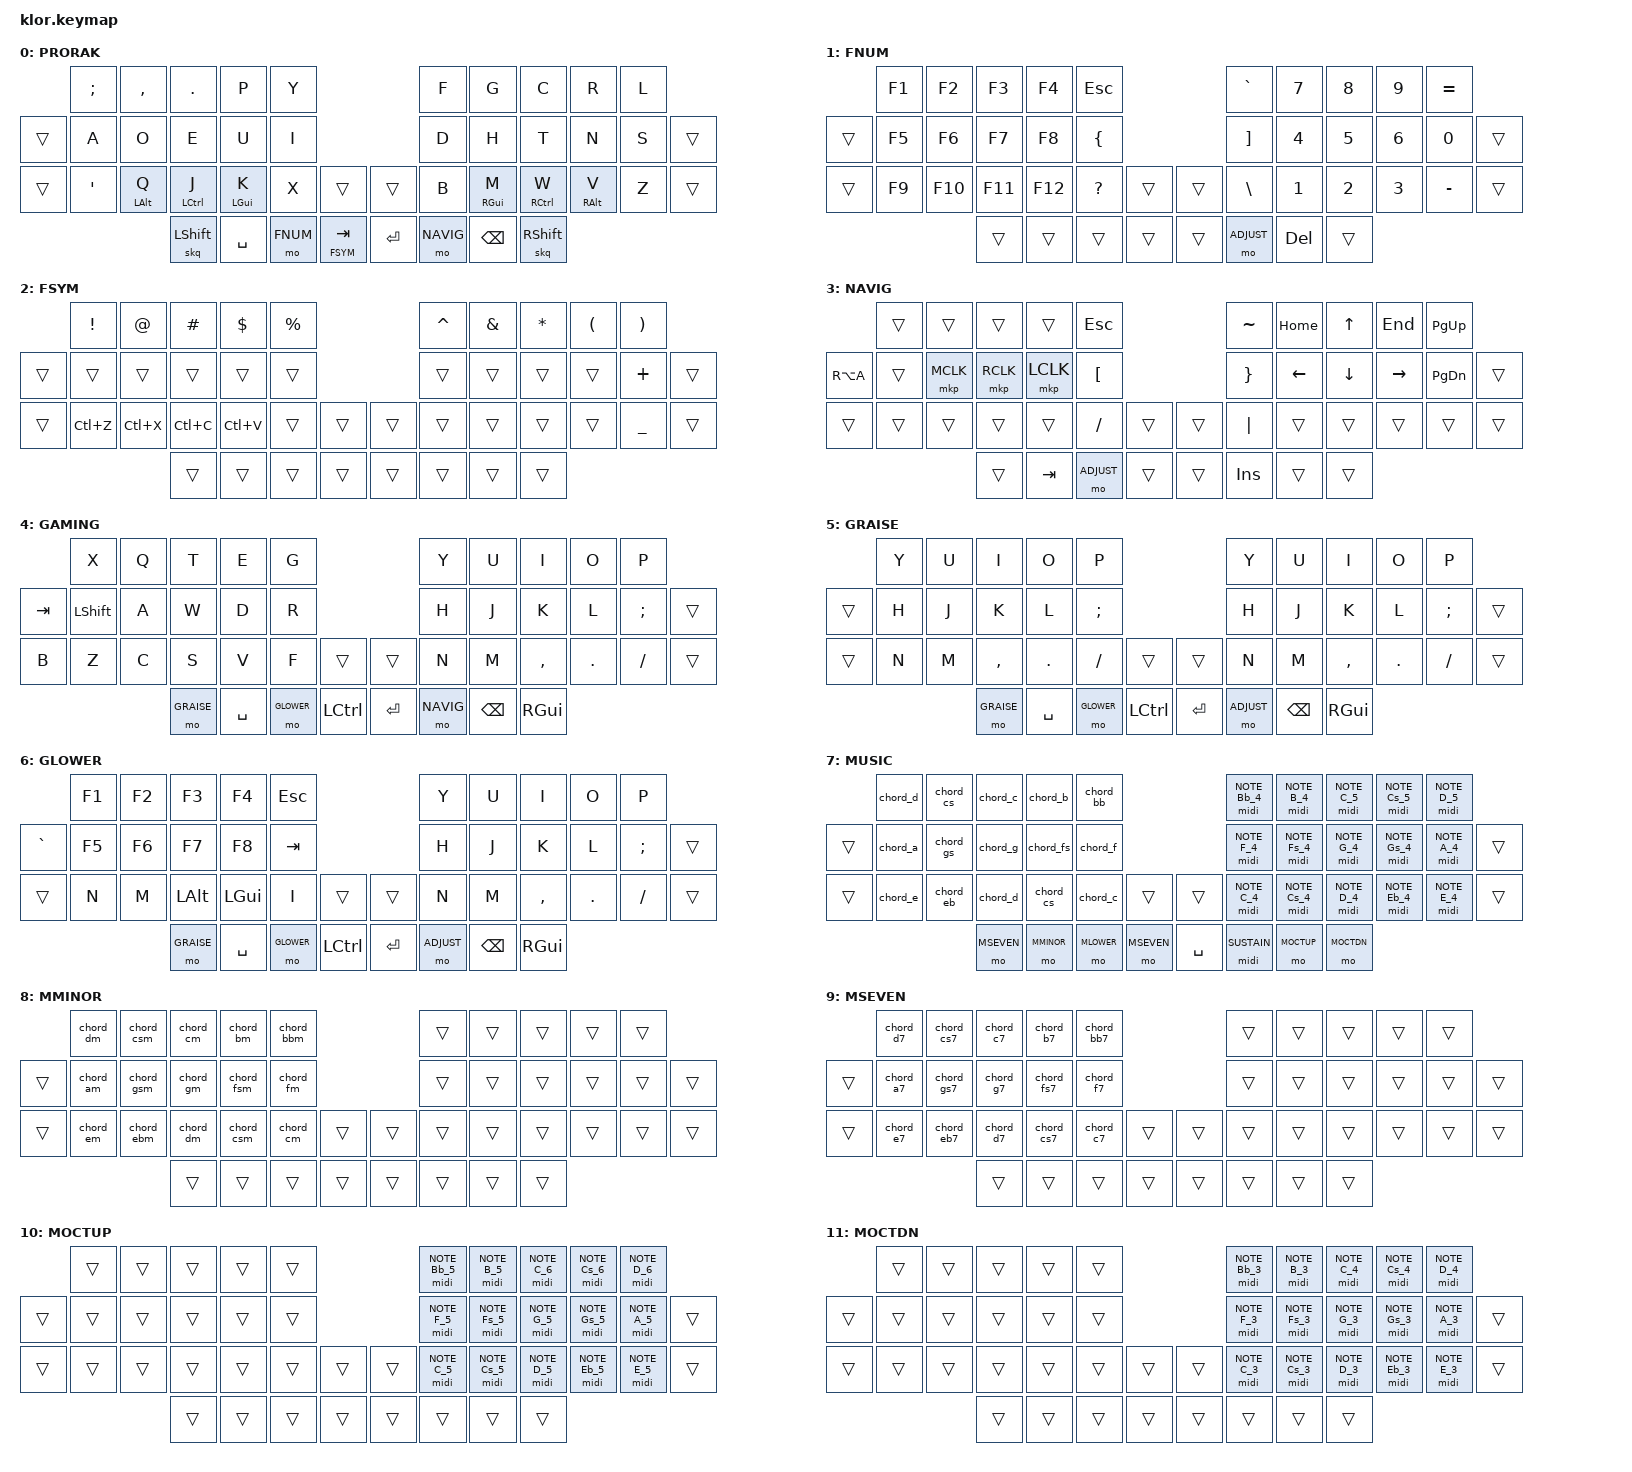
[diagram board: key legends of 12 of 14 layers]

//                               █         █    █            ▄▄▄▀▀▀▀▀▀▄▄▄        █▀▀▀▀▀▀▀▀▀▀█
//                               █        █     █          ▄▀            ▀▄      █          █
//                               █       █      █        ▄▀                ▀▄    █          █
//                               █      █       █        █                  █    █          █
//                               █     █        █       █                    █   █          █
//                               █    █         █       █                    █   █▄▄▄▄▄▄▄▄▄▄█
//                               █   █ █        █       █                    █   █      █
//                               █  █   █       █        █                  █    █       █
//                               █ █     █      █        ▀▄                ▄▀    █        █
//                               ██       █     █          ▀▄            ▄▀      █         █
//                               █         █    █▄▄▄▄▄▄▄▄    ▀▀▀▄▄▄▄▄▄▀▀▀        █          █
//
// ▄▄▄▄▄▄▄▄▄▄▄▄▄▄▄▄▄▄▄▄▄▄▄▄▄▄▄▄▄▄▄▄▄▄▄▄▄▄▄▄▄▄▄▄▄▄▄▄▄▄▄▄▄▄▄▄▄▄▄▄▄▄▄▄▄▄▄▄▄▄▄▄▄▄▄▄▄▄▄▄▄▄▄▄▄▄▄▄▄▄▄▄▄▄▄▄▄▄▄▄▄▄▄▄▄▄▄▄▄▄▄▄▄▄▄▄▄▄▄▄▄▄▄▄▄
       
#include <behaviors.dtsi>
#include <dt-bindings/zmk/keys.h>
#include <dt-bindings/zmk/bt.h>
#include <dt-bindings/zmk/outputs.h>
#include <dt-bindings/zmk/ext_power.h>
#include <dt-bindings/zmk/pointing.h>
#include <dt-bindings/zmk/midi.h>
#include <behaviors/midi_key_press.dtsi>
/* #include <dt-bindings/zmk/rgb.h> */


#define PRORAK 0
#define FNUM   1
#define FSYM   2
#define NAVIG  3
#define GAMING 4
#define GRAISE 5
#define GLOWER 6
#define MUSIC  7
#define MMINOR 8
#define MSEVEN 9
#define MOCTUP 10
#define MOCTDN 11
#define MLOWER 12
#define ADJUST 13


/* key positions
              ┌─────────┬─────────┬─────────┬─────────┬─────────┐                    ┌─────────┬─────────┬─────────┬─────────┬─────────┐
              │    0    │    1    │    2    │    3    │    4    │                    │    5    │    6    │    7    │    8    │    9    │   
    ┌─────────┼─────────┼─────────┼─────────┼─────────┼─────────┤                    ├─────────┼─────────┼─────────┼─────────┼─────────┼─────────┐
    │   10    │    11   │    12   │    13   │    14   │    15   │                    │    16   │    17   │    18   │    19   │    20   │    21   │
    ├─────────┼─────────┼─────────┼─────────┼─────────┼─────────┤╭────────╮╭────────╮├─────────┼─────────┼─────────┼─────────┼─────────┼─────────┤
    │   22    │    23   │    24   │    25   │    26   │    27   ││   28   ││   29   ││    30   │    31   │    32   │    33   │    34   │    35   │
    └─────────┴─────────┴─────────┼─────────┼─────────┼─────────┼╰────────╯╰────────╯┼─────────┼─────────┼─────────┼─────────┴─────────┴─────────┘
                                  │    36   │    37   │    38   │    39   ││   40    │    41   │    42   │    43   │
                                  └─────────┴─────────┴─────────┴─────────┘└─────────┴─────────┴─────────┴─────────┘ */ 

/ {
    behaviors {
        hml: left_hand_mods {
            compatible = "zmk,behavior-hold-tap";
            label = "BOTTOMROW_MODS_LEFT";
            #binding-cells = <2>;
            tapping-term-ms = <170>;
            require-prior-idle-ms = <110>; // prevents firing during fast typing rolls
            quick-tap-ms = <100>; // tap-hold to spam keys, default 0
            //  the whitelisted key will trigger the mod key immediately
            hold-trigger-key-positions = <
                                          5  6  7  8  9
                                         16 17 18 19 20 21
                                         30 31 32 33 34 35
                                      40 41    43

                    24 25 26
                       36    38 39
            >;
            // flavor = "tap-preferred";
            flavor = "balanced"; // apply modifiers immediately when a key on the other half is pressed
            bindings = <&kp>, <&kp>;

        };
        hmr: right_hand_mods {
            compatible = "zmk,behavior-hold-tap";
            label = "BOTTOMROW_MODS_RIGHT";
            #binding-cells = <2>;
            tapping-term-ms = <170>;
            require-prior-idle-ms = <110>; // prevents firing during fast typing rolls
            quick-tap-ms = <100>; // tap-hold to spam keys, default 0
            //  the whitelisted key will trigger the mod key immediately
            hold-trigger-key-positions = <
                                            31 32 33
                                      40 41    43

                  0  1  2  3  4
              10 11 12 13 14 15
              22 23 24 25 26 27
                       36    38 39
            >;
            // flavor = "tap-preferred";
            flavor = "balanced"; // apply modifiers immediately when a key the other half is pressed
            bindings = <&kp>, <&kp>;

        };
        skq: sticky_key_quick_release {
            compatible = "zmk,behavior-sticky-key";
            #binding-cells = <1>;
            bindings = <&kp>;
            release-after-ms = <500>;
            quick-release; // Release after a button is pressed (to avoid rolling CAPS)
            ignore-modifiers;  // Recommended for shift
        };

        lt_tmb: layer_tap_thumb {
            compatible = "zmk,behavior-hold-tap";
            label = "LAYER_TAP_THUMB";
            #binding-cells = <2>;
            tapping-term-ms = <200>;
            quick-tap-ms = <100>;
            flavor = "hold-preferred"; // allows fast rolls
            bindings = <&mo>, <&kp>;
        };

    };

     combos {
            compatible = "zmk,combos";
            combo_adjust {
              timeout-ms = <50>;
              key-positions = <40 42>; // ENTER + BSPC
              bindings = <&mo ADJUST>;
            };
            combo_caps_word {
              timeout-ms = <50>;
              key-positions = <36 43>; // LSHFT (Left most Thumb) + RSHFT (Right most Thumb)
              bindings = <&caps_word>;
            };
    };

    macros {
        // --- 12 Major Chords ---
        chord_c: chord_c {
            compatible = "zmk,behavior-macro";
            #binding-cells = <0>;
            bindings = <&macro_press &midi NOTE_C_4 &midi NOTE_E_4 &midi NOTE_G_4>
                     , <&macro_pause_for_release>
                     , <&macro_release &midi NOTE_C_4 &midi NOTE_E_4 &midi NOTE_G_4>;
        };

        chord_cs: chord_cs {
            compatible = "zmk,behavior-macro";
            #binding-cells = <0>;
            bindings = <&macro_press &midi NOTE_Cs_4 &midi NOTE_F_4 &midi NOTE_Gs_4>
                     , <&macro_pause_for_release>
                     , <&macro_release &midi NOTE_Cs_4 &midi NOTE_F_4 &midi NOTE_Gs_4>;
        };

        chord_d: chord_d {
            compatible = "zmk,behavior-macro";
            #binding-cells = <0>;
            bindings = <&macro_press &midi NOTE_D_4 &midi NOTE_Fs_4 &midi NOTE_A_4>
                     , <&macro_pause_for_release>
                     , <&macro_release &midi NOTE_D_4 &midi NOTE_Fs_4 &midi NOTE_A_4>;
        };

        chord_eb: chord_eb {
            compatible = "zmk,behavior-macro";
            #binding-cells = <0>;
            bindings = <&macro_press &midi NOTE_Eb_4 &midi NOTE_G_4 &midi NOTE_Bb_4>
                     , <&macro_pause_for_release>
                     , <&macro_release &midi NOTE_Eb_4 &midi NOTE_G_4 &midi NOTE_Bb_4>;
        };

        chord_e: chord_e {
            compatible = "zmk,behavior-macro";
            #binding-cells = <0>;
            bindings = <&macro_press &midi NOTE_E_4 &midi NOTE_Gs_4 &midi NOTE_B_4>
                     , <&macro_pause_for_release>
                     , <&macro_release &midi NOTE_E_4 &midi NOTE_Gs_4 &midi NOTE_B_4>;
        };

        chord_f: chord_f {
            compatible = "zmk,behavior-macro";
            #binding-cells = <0>;
            bindings = <&macro_press &midi NOTE_F_4 &midi NOTE_A_4 &midi NOTE_C_5>
                     , <&macro_pause_for_release>
                     , <&macro_release &midi NOTE_F_4 &midi NOTE_A_4 &midi NOTE_C_5>;
        };

        chord_fs: chord_fs {
            compatible = "zmk,behavior-macro";
            #binding-cells = <0>;
            bindings = <&macro_press &midi NOTE_Fs_4 &midi NOTE_Bb_4 &midi NOTE_Cs_5>
                     , <&macro_pause_for_release>
                     , <&macro_release &midi NOTE_Fs_4 &midi NOTE_Bb_4 &midi NOTE_Cs_5>;
        };

        chord_g: chord_g {
            compatible = "zmk,behavior-macro";
            #binding-cells = <0>;
            bindings = <&macro_press &midi NOTE_G_4 &midi NOTE_B_4 &midi NOTE_D_5>
                     , <&macro_pause_for_release>
                     , <&macro_release &midi NOTE_G_4 &midi NOTE_B_4 &midi NOTE_D_5>;
        };

        chord_gs: chord_gs {
            compatible = "zmk,behavior-macro";
            #binding-cells = <0>;
            bindings = <&macro_press &midi NOTE_Gs_4 &midi NOTE_C_5 &midi NOTE_Eb_5>
                     , <&macro_pause_for_release>
                     , <&macro_release &midi NOTE_Gs_4 &midi NOTE_C_5 &midi NOTE_Eb_5>;
        };

        chord_a: chord_a {
            compatible = "zmk,behavior-macro";
            #binding-cells = <0>;
            bindings = <&macro_press &midi NOTE_A_4 &midi NOTE_Cs_5 &midi NOTE_E_5>
                     , <&macro_pause_for_release>
                     , <&macro_release &midi NOTE_A_4 &midi NOTE_Cs_5 &midi NOTE_E_5>;
        };

        chord_bb: chord_bb {
            compatible = "zmk,behavior-macro";
            #binding-cells = <0>;
            bindings = <&macro_press &midi NOTE_Bb_4 &midi NOTE_D_5 &midi NOTE_F_5>
                     , <&macro_pause_for_release>
                     , <&macro_release &midi NOTE_Bb_4 &midi NOTE_D_5 &midi NOTE_F_5>;
        };

        chord_b: chord_b {
            compatible = "zmk,behavior-macro";
            #binding-cells = <0>;
            bindings = <&macro_press &midi NOTE_B_4 &midi NOTE_Ds_5 &midi NOTE_Fs_5>
                     , <&macro_pause_for_release>
                     , <&macro_release &midi NOTE_B_4 &midi NOTE_Ds_5 &midi NOTE_Fs_5>;
        };

        // --- 12 Minor Chords ---
        chord_cm: chord_cm {
            compatible = "zmk,behavior-macro";
            #binding-cells = <0>;
            bindings = <&macro_press &midi NOTE_C_4 &midi NOTE_Eb_4 &midi NOTE_G_4>
                     , <&macro_pause_for_release>
                     , <&macro_release &midi NOTE_C_4 &midi NOTE_Eb_4 &midi NOTE_G_4>;
        };

        chord_csm: chord_csm {
            compatible = "zmk,behavior-macro";
            #binding-cells = <0>;
            bindings = <&macro_press &midi NOTE_Cs_4 &midi NOTE_E_4 &midi NOTE_Gs_4>
                     , <&macro_pause_for_release>
                     , <&macro_release &midi NOTE_Cs_4 &midi NOTE_E_4 &midi NOTE_Gs_4>;
        };

        chord_dm: chord_dm {
            compatible = "zmk,behavior-macro";
            #binding-cells = <0>;
            bindings = <&macro_press &midi NOTE_D_4 &midi NOTE_F_4 &midi NOTE_A_4>
                     , <&macro_pause_for_release>
                     , <&macro_release &midi NOTE_D_4 &midi NOTE_F_4 &midi NOTE_A_4>;
        };

        chord_ebm: chord_ebm {
            compatible = "zmk,behavior-macro";
            #binding-cells = <0>;
            bindings = <&macro_press &midi NOTE_Eb_4 &midi NOTE_Fs_4 &midi NOTE_Bb_4>
                     , <&macro_pause_for_release>
                     , <&macro_release &midi NOTE_Eb_4 &midi NOTE_Fs_4 &midi NOTE_Bb_4>;
        };

        chord_em: chord_em {
            compatible = "zmk,behavior-macro";
            #binding-cells = <0>;
            bindings = <&macro_press &midi NOTE_E_4 &midi NOTE_G_4 &midi NOTE_B_4>
                     , <&macro_pause_for_release>
                     , <&macro_release &midi NOTE_E_4 &midi NOTE_G_4 &midi NOTE_B_4>;
        };

        chord_fm: chord_fm {
            compatible = "zmk,behavior-macro";
            #binding-cells = <0>;
            bindings = <&macro_press &midi NOTE_F_4 &midi NOTE_Gs_4 &midi NOTE_C_5>
                     , <&macro_pause_for_release>
                     , <&macro_release &midi NOTE_F_4 &midi NOTE_Gs_4 &midi NOTE_C_5>;
        };

        chord_fsm: chord_fsm {
            compatible = "zmk,behavior-macro";
            #binding-cells = <0>;
            bindings = <&macro_press &midi NOTE_Fs_4 &midi NOTE_A_4 &midi NOTE_Cs_5>
                     , <&macro_pause_for_release>
                     , <&macro_release &midi NOTE_Fs_4 &midi NOTE_A_4 &midi NOTE_Cs_5>;
        };

        chord_gm: chord_gm {
            compatible = "zmk,behavior-macro";
            #binding-cells = <0>;
            bindings = <&macro_press &midi NOTE_G_4 &midi NOTE_Bb_4 &midi NOTE_D_5>
                     , <&macro_pause_for_release>
                     , <&macro_release &midi NOTE_G_4 &midi NOTE_Bb_4 &midi NOTE_D_5>;
        };

        chord_gsm: chord_gsm {
            compatible = "zmk,behavior-macro";
            #binding-cells = <0>;
            bindings = <&macro_press &midi NOTE_Gs_4 &midi NOTE_B_4 &midi NOTE_Eb_5>
                     , <&macro_pause_for_release>
                     , <&macro_release &midi NOTE_Gs_4 &midi NOTE_B_4 &midi NOTE_Eb_5>;
        };

        chord_am: chord_am {
            compatible = "zmk,behavior-macro";
            #binding-cells = <0>;
            bindings = <&macro_press &midi NOTE_A_4 &midi NOTE_C_5 &midi NOTE_E_5>
                     , <&macro_pause_for_release>
                     , <&macro_release &midi NOTE_A_4 &midi NOTE_C_5 &midi NOTE_E_5>;
        };

        chord_bbm: chord_bbm {
            compatible = "zmk,behavior-macro";
            #binding-cells = <0>;
            bindings = <&macro_press &midi NOTE_Bb_4 &midi NOTE_Cs_5 &midi NOTE_F_5>
                     , <&macro_pause_for_release>
                     , <&macro_release &midi NOTE_Bb_4 &midi NOTE_Cs_5 &midi NOTE_F_5>;
        };

        chord_bm: chord_bm {
            compatible = "zmk,behavior-macro";
            #binding-cells = <0>;
            bindings = <&macro_press &midi NOTE_B_4 &midi NOTE_D_5 &midi NOTE_Fs_5>
                     , <&macro_pause_for_release>
                     , <&macro_release &midi NOTE_B_4 &midi NOTE_D_5 &midi NOTE_Fs_5>;
        };

        // --- 12 Dominant 7th Chords ---
        chord_c7: chord_c7 {
            compatible = "zmk,behavior-macro";
            #binding-cells = <0>;
            bindings = <&macro_press &midi NOTE_C_4 &midi NOTE_E_4 &midi NOTE_G_4 &midi NOTE_Bb_4>
                     , <&macro_pause_for_release>
                     , <&macro_release &midi NOTE_C_4 &midi NOTE_E_4 &midi NOTE_G_4 &midi NOTE_Bb_4>;
        };

        chord_cs7: chord_cs7 {
            compatible = "zmk,behavior-macro";
            #binding-cells = <0>;
            bindings = <&macro_press &midi NOTE_Cs_4 &midi NOTE_F_4 &midi NOTE_Gs_4 &midi NOTE_B_4>
                     , <&macro_pause_for_release>
                     , <&macro_release &midi NOTE_Cs_4 &midi NOTE_F_4 &midi NOTE_Gs_4 &midi NOTE_B_4>;
        };

        chord_d7: chord_d7 {
            compatible = "zmk,behavior-macro";
            #binding-cells = <0>;
            bindings = <&macro_press &midi NOTE_D_4 &midi NOTE_Fs_4 &midi NOTE_A_4 &midi NOTE_C_5>
                     , <&macro_pause_for_release>
                     , <&macro_release &midi NOTE_D_4 &midi NOTE_Fs_4 &midi NOTE_A_4 &midi NOTE_C_5>;
        };

        chord_eb7: chord_eb7 {
            compatible = "zmk,behavior-macro";
            #binding-cells = <0>;
            bindings = <&macro_press &midi NOTE_Eb_4 &midi NOTE_G_4 &midi NOTE_Bb_4 &midi NOTE_Cs_5>
                     , <&macro_pause_for_release>
                     , <&macro_release &midi NOTE_Eb_4 &midi NOTE_G_4 &midi NOTE_Bb_4 &midi NOTE_Cs_5>;
        };

        chord_e7: chord_e7 {
            compatible = "zmk,behavior-macro";
            #binding-cells = <0>;
            bindings = <&macro_press &midi NOTE_E_4 &midi NOTE_Gs_4 &midi NOTE_B_4 &midi NOTE_D_5>
                     , <&macro_pause_for_release>
                     , <&macro_release &midi NOTE_E_4 &midi NOTE_Gs_4 &midi NOTE_B_4 &midi NOTE_D_5>;
        };

        chord_f7: chord_f7 {
            compatible = "zmk,behavior-macro";
            #binding-cells = <0>;
            bindings = <&macro_press &midi NOTE_F_4 &midi NOTE_A_4 &midi NOTE_C_5 &midi NOTE_Eb_5>
                     , <&macro_pause_for_release>
                     , <&macro_release &midi NOTE_F_4 &midi NOTE_A_4 &midi NOTE_C_5 &midi NOTE_Eb_5>;
        };

        chord_fs7: chord_fs7 {
            compatible = "zmk,behavior-macro";
            #binding-cells = <0>;
            bindings = <&macro_press &midi NOTE_Fs_4 &midi NOTE_Bb_4 &midi NOTE_Cs_5 &midi NOTE_E_5>
                     , <&macro_pause_for_release>
                     , <&macro_release &midi NOTE_Fs_4 &midi NOTE_Bb_4 &midi NOTE_Cs_5 &midi NOTE_E_5>;
        };

        chord_g7: chord_g7 {
            compatible = "zmk,behavior-macro";
            #binding-cells = <0>;
            bindings = <&macro_press &midi NOTE_G_4 &midi NOTE_B_4 &midi NOTE_D_5 &midi NOTE_F_5>
                     , <&macro_pause_for_release>
                     , <&macro_release &midi NOTE_G_4 &midi NOTE_B_4 &midi NOTE_D_5 &midi NOTE_F_5>;
        };

        chord_gs7: chord_gs7 {
            compatible = "zmk,behavior-macro";
            #binding-cells = <0>;
            bindings = <&macro_press &midi NOTE_Gs_4 &midi NOTE_C_5 &midi NOTE_Eb_5 &midi NOTE_Fs_5>
                     , <&macro_pause_for_release>
                     , <&macro_release &midi NOTE_Gs_4 &midi NOTE_C_5 &midi NOTE_Eb_5 &midi NOTE_Fs_5>;
        };

        chord_a7: chord_a7 {
            compatible = "zmk,behavior-macro";
            #binding-cells = <0>;
            bindings = <&macro_press &midi NOTE_A_4 &midi NOTE_Cs_5 &midi NOTE_E_5 &midi NOTE_G_5>
                     , <&macro_pause_for_release>
                     , <&macro_release &midi NOTE_A_4 &midi NOTE_Cs_5 &midi NOTE_E_5 &midi NOTE_G_5>;
        };

        chord_bb7: chord_bb7 {
            compatible = "zmk,behavior-macro";
            #binding-cells = <0>;
            bindings = <&macro_press &midi NOTE_Bb_4 &midi NOTE_D_5 &midi NOTE_F_5 &midi NOTE_Gs_5>
                     , <&macro_pause_for_release>
                     , <&macro_release &midi NOTE_Bb_4 &midi NOTE_D_5 &midi NOTE_F_5 &midi NOTE_Gs_5>;
        };

        chord_b7: chord_b7 {
            compatible = "zmk,behavior-macro";
            #binding-cells = <0>;
            bindings = <&macro_press &midi NOTE_B_4 &midi NOTE_Ds_5 &midi NOTE_Fs_5 &midi NOTE_A_5>
                     , <&macro_pause_for_release>
                     , <&macro_release &midi NOTE_B_4 &midi NOTE_Ds_5 &midi NOTE_Fs_5 &midi NOTE_A_5>;
        };
    };

    keymap {
        compatible = "zmk,keymap";
// ▄▄▄▄▄▄▄▄▄▄▄▄▄▄▄▄▄▄▄▄▄▄▄▄▄▄▄▄▄▄▄▄▄▄▄▄▄▄▄▄▄▄▄▄▄▄▄▄▄▄▄▄▄▄▄▄▄▄▄▄▄▄▄▄▄▄▄▄▄▄▄▄▄▄▄▄▄▄▄▄▄▄▄▄▄▄▄▄▄▄▄▄▄▄▄▄▄▄▄▄▄▄▄▄▄▄▄▄▄▄▄▄▄▄▄▄▄▄▄▄▄▄▄▄▄▄▄▄▄▄▄▄▄▄▄▄▄▄▄▄▄▄


                prorak_layer {
//  ┌───────────────────────────────────────────────────────────┐
label= "PRORAK"                                                 ;
//  └───────────────────────────────────────────────────────────┘
/*            ┌─────────┬─────────┬─────────┬─────────┬─────────┐                    ┌─────────┬─────────┬─────────┬─────────┬─────────┐
              │    ;    │    ,    │    .    │    P    │    Y    │                    │    F    │    G    │    C    │    R    │    L    │
    ┌─────────┼─────────┼─────────┼─────────┼─────────┼─────────┤                    ├─────────┼─────────┼─────────┼─────────┼─────────┼─────────┐
    │   XXX   │    A    │    O    │    E    │    U    │    I    │                    │    D    │    H    │    T    │    N    │    S    │   XXX   │
    ├─────────┼─────────┼─────────┼─────────┼─────────┼─────────┤╭────────╮╭────────╮├─────────┼─────────┼─────────┼─────────┼─────────┼─────────┤
    │   XXX   │    "    │ Q/LALT  │ J/LCTRL │ K/LGUI  │    X    ││  MUTE  ││PLY/PSE ││    B    │ M/RGUI  │ W/RCTRL │ V/RALT  │    Z    │   XXX   │
    └─────────┴─────────┴─────────┼─────────┼─────────┼─────────┼╰────────╯╰────────╯┼─────────┼─────────┼─────────┼─────────┴─────────┴─────────┘
                                  │  LSHFT  │  SPACE  │  FNUM   │ TAB/FSYM││  ENTER  │  NAVIG  │  BSPCE  │  RSHFT  │
                                  └─────────┴─────────┴─────────┴─────────┘└─────────┴─────────┴─────────┴─────────┘ */
 bindings = <
 //|          ╷         ╷           ╷            ╷           ╷         ╷               ╷╷         ╷         ╷           ╷            ╷           ╷         ╷
              &kp SEMI  &kp COMMA   &kp DOT      &kp P       &kp Y                                &kp F     &kp G       &kp C        &kp R       &kp L
    &trans    &kp A     &kp O       &kp E        &kp U       &kp I                                &kp D     &kp H       &kp T        &kp N       &kp S      &trans
    &trans    &kp SQT   &hml LALT Q &hml LCTRL J &hml LGUI K &kp X     &trans           &trans    &kp B     &hmr RGUI M &hmr RCTRL W &hmr RALT V &kp Z      &trans
                                    &skq LSHFT   &kp SPACE   &mo FNUM  &lt_tmb FSYM TAB &kp RET   &mo NAVIG &kp BSPC    &skq RSHFT
 //|          ╷         ╷           ╷            ╷           ╷         ╷               ╷╷         ╷         ╷           ╷            ╷           ╷         ╷
                        >;
            sensor-bindings = <&inc_dec_kp C_VOL_UP C_VOL_DN>;
                };

// ▄▄▄▄▄▄▄▄▄▄▄▄▄▄▄▄▄▄▄▄▄▄▄▄▄▄▄▄▄▄▄▄▄▄▄▄▄▄▄▄▄▄▄▄▄▄▄▄▄▄▄▄▄▄▄▄▄▄▄▄▄▄▄▄▄▄▄▄▄▄▄▄▄▄▄▄▄▄▄▄▄▄▄▄▄▄▄▄▄▄▄▄▄▄▄▄▄▄▄▄▄▄▄▄▄▄▄▄▄▄▄▄▄▄▄▄▄▄▄▄▄▄▄▄▄▄▄▄▄▄▄▄▄▄▄▄▄▄▄▄▄▄


                fnum_layer {
//  ┌───────────────────────────────────────────────────────────┐
label= "FNUM"                                                   ;
//  └───────────────────────────────────────────────────────────┘
/*            ┌─────────┬─────────┬─────────┬─────────┬─────────┐                    ┌─────────┬─────────┬─────────┬─────────┬─────────┐
              │   F1    │   F2    │   F3    │   F4    │   ESC   │                    │    `    │    7    │    8    │    9    │    0    │
    ┌─────────┼─────────┼─────────┼─────────┼─────────┼─────────┤                    ├─────────┼─────────┼─────────┼─────────┼─────────┼─────────┐
    │         │   F5    │   F6    │   F7    │   F8    │    {    │                    │    ]    │    4    │    5    │    6    │    =    │         │
    ├─────────┼─────────┼─────────┼─────────┼─────────┼─────────┤╭────────╮╭────────╮├─────────┼─────────┼─────────┼─────────┼─────────┼─────────┤
    │         │   F9    │   F10   │   F11   │   F12   │    ?    ││        ││        ││    \    │    1    │    2    │    3    │    -    │         │
    └─────────┴─────────┴─────────┼─────────┼─────────┼─────────┼╰────────╯╰────────╯┼─────────┼─────────┼─────────┼─────────┴─────────┴─────────┘
                                  │         │         │         │         ││         │  ADJUST │ DELETE  │         │  
                                  └─────────┴─────────┴─────────┴─────────┘└─────────┴─────────┴─────────┴─────────┘ */ 
 bindings = <
 //|          ╷         ╷         ╷         ╷         ╷         ╷         ╷╷         ╷         ╷         ╷         ╷         ╷         ╷
              &kp F1    &kp F2    &kp F3    &kp F4    &kp ESC                        &kp GRAVE &kp N7    &kp N8    &kp N9    &kp EQUAL
    &trans    &kp F5    &kp F6    &kp F7    &kp F8    &kp LBRC                       &kp RBKT  &kp N4    &kp N5    &kp N6    &kp N0    &trans
    &trans    &kp F9    &kp F10   &kp F11   &kp F12   &kp QMARK &trans     &trans    &kp BSLH  &kp N1    &kp N2    &kp N3    &kp MINUS &trans
                                  &trans    &trans    &trans    &trans     &trans    &mo ADJUST &kp DELETE &trans
                        >;
            sensor-bindings = <&inc_dec_kp C_VOL_UP C_VOL_DN>;
                };

// ▄▄▄▄▄▄▄▄▄▄▄▄▄▄▄▄▄▄▄▄▄▄▄▄▄▄▄▄▄▄▄▄▄▄▄▄▄▄▄▄▄▄▄▄▄▄▄▄▄▄▄▄▄▄▄▄▄▄▄▄▄▄▄▄▄▄▄▄▄▄▄▄▄▄▄▄▄▄▄▄▄▄▄▄▄▄▄▄▄▄▄▄▄▄▄▄▄▄▄▄▄▄▄▄▄▄▄▄▄▄▄▄▄▄▄▄▄▄▄▄▄▄▄▄▄

                fsym_layer {
//  ┌───────────────────────────────────────────────────────────┐
label= "FSYM"                                                   ;
//  └───────────────────────────────────────────────────────────┘
/*            ┌─────────┬─────────┬─────────┬─────────┬─────────┐                    ┌─────────┬─────────┬─────────┬─────────┬─────────┐
              │    !    │    @    │    #    │    $    │    %    │                    │    ^    │    &    │    *    │    (    │    )    │
    ┌─────────┼─────────┼─────────┼─────────┼─────────┼─────────┤                    ├─────────┼─────────┼─────────┼─────────┼─────────┼─────────┐
    │         │         │         │         │         │         │                    │         │         │         │         │    +    │         │
    ├─────────┼─────────┼─────────┼─────────┼─────────┼─────────┤╭────────╮╭────────╮├─────────┼─────────┼─────────┼─────────┼─────────┼─────────┤
    │         │   UNDO  │   CUT   │   COPY  │  PASTE  │         ││        ││        ││         │         │         │         │    _    │         │
    └─────────┴─────────┴─────────┼─────────┼─────────┼─────────┼╰────────╯╰────────╯┼─────────┼─────────┼─────────┼─────────┴─────────┴─────────┘
                                  │         │         │         │         ││         │         │         │         │
                                  └─────────┴─────────┴─────────┴─────────┘└─────────┴─────────┴─────────┴─────────┘ */
 bindings = <
 //|          ╷         ╷         ╷         ╷         ╷         ╷         ╷╷         ╷         ╷         ╷         ╷         ╷         ╷
              &kp EXCL  &kp AT    &kp HASH  &kp DLLR  &kp PRCNT                      &kp CARET &kp AMPS  &kp STAR  &kp LPAR  &kp RPAR
    &trans    &trans    &trans    &trans    &trans    &trans                         &trans    &trans    &trans    &trans    &kp PLUS  &trans
    &trans    &kp LC(Z) &kp LC(X) &kp LC(C) &kp LC(V) &trans    &trans     &trans    &trans    &trans    &trans    &trans    &kp UNDER &trans
                                  &trans    &trans    &trans    &trans     &trans    &trans    &trans    &trans
                        >;
                };

// ▄▄▄▄▄▄▄▄▄▄▄▄▄▄▄▄▄▄▄▄▄▄▄▄▄▄▄▄▄▄▄▄▄▄▄▄▄▄▄▄▄▄▄▄▄▄▄▄▄▄▄▄▄▄▄▄▄▄▄▄▄▄▄▄▄▄▄▄▄▄▄▄▄▄▄▄▄▄▄▄▄▄▄▄▄▄▄▄▄▄▄▄▄▄▄▄▄▄▄▄▄▄▄▄▄▄▄▄▄▄▄▄▄▄▄▄▄▄▄▄▄▄▄▄▄




                navig_layer {
//  ┌───────────────────────────────────────────────────────────┐
label= "NAVIG"                                                  ;
//  └───────────────────────────────────────────────────────────┘
/*           ┌─────────┬─────────┬─────────┬─────────┬─────────┐                    ┌─────────┬─────────┬─────────┬─────────┬─────────┐
             │         │         │         │         │   ESC   │                    │    ~    │   HOME  │   UP    │  END    │  PG UP  │
   ┌─────────┼─────────┼─────────┼─────────┼─────────┼─────────┤                    ├─────────┼─────────┼─────────┼─────────┼─────────┼─────────┐
   │         │         │ Mouse M │ Mouse R │ Mouse L │    [    │                    │    }    │   LEFT  │  DOWN   │  RIGHT  │ PG DOWN │         │
   ├─────────┼─────────┼─────────┼─────────┼─────────┼─────────┤╭────────╮╭────────╮├─────────┼─────────┼─────────┼─────────┼─────────┼─────────┤
   │         │         │         │         │         │    /    ││        ││        ││    |    │         │         │         │         │         │
   └─────────┴─────────┴─────────┼─────────┼─────────┼─────────┼╰────────╯╰────────╯┼─────────┼─────────┼─────────┼─────────┴─────────┴─────────┘
                                 │         │   TAB   │  ADJUST │         ││         │  INSERT │         │         │
                                 └─────────┴─────────┴─────────┴─────────┘└─────────┴─────────┴─────────┴─────────┘ */
 bindings = <
 //╷         ╷         ╷         ╷         ╷         ╷         ╷         ╷╷         ╷         ╷         ╷         ╷         ╷         ╷         ╷
              &trans    &trans    &trans    &trans    &kp ESC                        &kp TILDE  &kp HOME  &kp UP    &kp END   &kp PG_UP
    &kp RA(A) &trans    &mkp MCLK &mkp RCLK &mkp LCLK &kp LBKT                       &kp RBRC   &kp LEFT  &kp DOWN  &kp RIGHT &kp PG_DN &trans
    &trans    &trans    &trans    &trans    &trans    &kp FSLH  &trans     &trans    &kp PIPE   &trans    &trans    &trans    &trans    &trans
                                  &trans    &kp TAB   &mo ADJUST &trans    &trans    &kp INSERT &trans    &trans
                        >;
                sensor-bindings = <&inc_dec_kp C_VOL_UP C_VOL_DN>;
                };

// ▄▄▄▄▄▄▄▄▄▄▄▄▄▄▄▄▄▄▄▄▄▄▄▄▄▄▄▄▄▄▄▄▄▄▄▄▄▄▄▄▄▄▄▄▄▄▄▄▄▄▄▄▄▄▄▄▄▄▄▄▄▄▄▄▄▄▄▄▄▄▄▄▄▄▄▄▄▄▄▄▄▄▄▄▄▄▄▄▄▄▄▄▄▄▄▄▄▄▄▄▄▄▄▄▄▄▄▄▄▄▄▄▄▄▄▄▄▄▄▄▄▄▄▄▄▄▄▄▄▄▄▄▄▄▄▄▄▄▄▄▄▄


                gaming_layer {
//  ┌───────────────────────────────────────────────────────────┐
label= "GAMING"                                                 ;
//  └───────────────────────────────────────────────────────────┘
/*            ┌─────────┬─────────┬─────────┬─────────┬─────────┐                    ┌─────────┬─────────┬─────────┬─────────┬─────────┐
              │    V    │    Q    │    T    │    E    │    G    │                    │    Y    │    U    │    I    │    O    │    P    │
    ┌─────────┼─────────┼─────────┼─────────┼─────────┼─────────┤                    ├─────────┼─────────┼─────────┼─────────┼─────────┼─────────┐
    │   TAB   │  LSHFT  │    A    │    W    │    D    │    R    │                    │    H    │    J    │    K    │    L    │    ;    │   XXX   │
    ├─────────┼─────────┼─────────┼─────────┼─────────┼─────────┤╭────────╮╭────────╮├─────────┼─────────┼─────────┼─────────┼─────────┼─────────┤
    │    B    │    Z    │    C    │    S    │    X    │    F    ││  MUTE  ││PLY/PSE ││    N    │    M    │    ,    │    .    │    /    │   XXX   │
    └─────────┴─────────┴─────────┼─────────┼─────────┼─────────┼╰────────╯╰────────╯┼─────────┼─────────┼─────────┼─────────┴─────────┴─────────┘
                                  │  GRAISE │  SPACE  │  GLOWER │  LCTRL  ││  ENTER  │  NAVIG  │  BSPCE  │  RGUI   │
                                  └─────────┴─────────┴─────────┴─────────┘└─────────┴─────────┴─────────┴─────────┘ */
 bindings = <
 //|          ╷         ╷         ╷         ╷          ╷         ╷          ╷╷         ╷         ╷         ╷         ╷         ╷         ╷
              &kp X     &kp Q     &kp T     &kp E      &kp G                           &kp Y     &kp U     &kp I     &kp O     &kp P
    &kp TAB   &kp LSHFT &kp A     &kp W     &kp D      &kp R                           &kp H     &kp J     &kp K     &kp L     &kp SEMI  &trans
    &kp B     &kp Z     &kp C     &kp S     &kp V      &kp F     &trans     &trans     &kp N     &kp M     &kp COMMA &kp DOT   &kp FSLH  &trans
                                            &mo GRAISE &kp SPACE &mo GLOWER &kp LCTRL  &kp RET   &mo NAVIG &kp BSPC  &kp RGUI
                        >;
            sensor-bindings = <&inc_dec_kp C_VOL_UP C_VOL_DN>;
                };

// ▄▄▄▄▄▄▄▄▄▄▄▄▄▄▄▄▄▄▄▄▄▄▄▄▄▄▄▄▄▄▄▄▄▄▄▄▄▄▄▄▄▄▄▄▄▄▄▄▄▄▄▄▄▄▄▄▄▄▄▄▄▄▄▄▄▄▄▄▄▄▄▄▄▄▄▄▄▄▄▄▄▄▄▄▄▄▄▄▄▄▄▄▄▄▄▄▄▄▄▄▄▄▄▄▄▄▄▄▄▄▄▄▄▄▄▄▄▄▄▄▄▄▄▄▄▄▄▄▄▄▄▄▄▄▄▄▄▄▄▄▄▄


                gaming_raise_layer {
//  ┌───────────────────────────────────────────────────────────┐
label= "GRAISE"                                                 ;
//  └───────────────────────────────────────────────────────────┘
/*            ┌─────────┬─────────┬─────────┬─────────┬─────────┐                    ┌─────────┬─────────┬─────────┬─────────┬─────────┐
              │    Y    │    U    │    I    │    O    │    P    │                    │    Y    │    U    │    I    │    O    │    P    │
    ┌─────────┼─────────┼─────────┼─────────┼─────────┼─────────┤                    ├─────────┼─────────┼─────────┼─────────┼─────────┼─────────┐
    │   XXX   │    H    │    J    │    K    │    L    │    ;    │                    │    H    │    J    │    K    │    L    │    ;    │   XXX   │
    ├─────────┼─────────┼─────────┼─────────┼─────────┼─────────┤╭────────╮╭────────╮├─────────┼─────────┼─────────┼─────────┼─────────┼─────────┤
    │   XXX   │    N    │    M    │    ,    │    .    │    /    ││  MUTE  ││PLY/PSE ││    N    │    M    │    ,    │    .    │    /    │   XXX   │
    └─────────┴─────────┴─────────┼─────────┼─────────┼─────────┼╰────────╯╰────────╯┼─────────┼─────────┼─────────┼─────────┴─────────┴─────────┘
                                  │  GRAISE │  SPACE  │  GLOWER │  LCTRL  ││  ENTER  │  NAVIG  │  BSPCE  │  RGUI   │
                                  └─────────┴─────────┴─────────┴─────────┘└─────────┴─────────┴─────────┴─────────┘ */
 bindings = <
 //|          ╷         ╷         ╷         ╷          ╷         ╷          ╷╷         ╷         ╷          ╷         ╷         ╷         ╷
              &kp Y     &kp U     &kp I     &kp O      &kp P                           &kp Y     &kp U      &kp I     &kp O     &kp P
    &trans    &kp H     &kp J     &kp K     &kp L      &kp SEMI                        &kp H     &kp J      &kp K     &kp L     &kp SEMI  &trans
    &trans    &kp N     &kp M     &kp COMMA &kp DOT    &kp FSLH  &trans     &trans     &kp N     &kp M      &kp COMMA &kp DOT   &kp FSLH  &trans
                                            &mo GRAISE &kp SPACE &mo GLOWER &kp LCTRL  &kp RET   &mo ADJUST &kp BSPC &kp RGUI
                        >;
            sensor-bindings = <&inc_dec_kp C_VOL_UP C_VOL_DN>;
                };

// ▄▄▄▄▄▄▄▄▄▄▄▄▄▄▄▄▄▄▄▄▄▄▄▄▄▄▄▄▄▄▄▄▄▄▄▄▄▄▄▄▄▄▄▄▄▄▄▄▄▄▄▄▄▄▄▄▄▄▄▄▄▄▄▄▄▄▄▄▄▄▄▄▄▄▄▄▄▄▄▄▄▄▄▄▄▄▄▄▄▄▄▄▄▄▄▄▄▄▄▄▄▄▄▄▄▄▄▄▄▄▄▄▄▄▄▄▄▄▄▄▄▄▄▄▄▄▄▄▄▄▄▄▄▄▄▄▄▄▄▄▄▄


                gaming_lower_layer {
//  ┌───────────────────────────────────────────────────────────┐
label= "GLOWER"                                                 ;
//  └───────────────────────────────────────────────────────────┘
/*            ┌─────────┬─────────┬─────────┬─────────┬─────────┐                    ┌─────────┬─────────┬─────────┬─────────┬─────────┐
              │    F1   │    F2   │    F3   │    F4   │   ESC   │                    │    Y    │    U    │    I    │    O    │    P    │
    ┌─────────┼─────────┼─────────┼─────────┼─────────┼─────────┤                    ├─────────┼─────────┼─────────┼─────────┼─────────┼─────────┐
    │   GRV   │    F5   │    F6   │    F7   │    F8   │   TAB   │                    │    H    │    J    │    K    │    L    │    ;    │   XXX   │
    ├─────────┼─────────┼─────────┼─────────┼─────────┼─────────┤╭────────╮╭────────╮├─────────┼─────────┼─────────┼─────────┼─────────┼─────────┤
    │   XXX   │    N    │    M    │   LALT  │  LGUI   │    I    ││  MUTE  ││PLY/PSE ││    N    │    M    │    ,    │    .    │    /    │   XXX   │
    └─────────┴─────────┴─────────┼─────────┼─────────┼─────────┼╰────────╯╰────────╯┼─────────┼─────────┼─────────┼─────────┴─────────┴─────────┘
                                  │  GRAISE │  SPACE  │  GLOWER │  LCTRL  ││  ENTER  │  ADJUST │  BSPCE  │  RGUI   │
                                  └─────────┴─────────┴─────────┴─────────┘└─────────┴─────────┴─────────┴─────────┘ */
 bindings = <
 //|          ╷         ╷         ╷         ╷          ╷         ╷          ╷╷         ╷         ╷         ╷         ╷         ╷         ╷
              &kp F1    &kp F2    &kp F3    &kp F4     &kp ESC                         &kp Y     &kp U     &kp I     &kp O     &kp P
    &kp GRAVE &kp F5    &kp F6    &kp F7    &kp F8     &kp TAB                         &kp H     &kp J     &kp K     &kp L     &kp SEMI  &trans
    &trans    &kp N     &kp M     &kp LALT  &kp LGUI   &kp I     &trans     &trans     &kp N     &kp M     &kp COMMA &kp DOT   &kp FSLH  &trans
                                            &mo GRAISE &kp SPACE &mo GLOWER &kp LCTRL  &kp RET   &mo ADJUST &kp BSPC &kp RGUI
                        >;
            sensor-bindings = <&inc_dec_kp C_VOL_UP C_VOL_DN>;
                };

// ▄▄▄▄▄▄▄▄▄▄▄▄▄▄▄▄▄▄▄▄▄▄▄▄▄▄▄▄▄▄▄▄▄▄▄▄▄▄▄▄▄▄▄▄▄▄▄▄▄▄▄▄▄▄▄▄▄▄▄▄▄▄▄▄▄▄▄▄▄▄▄▄▄▄▄▄▄▄▄▄▄▄▄▄▄▄▄▄▄▄▄▄▄▄▄▄▄▄▄▄▄▄▄▄▄▄▄▄▄▄▄▄▄▄▄▄▄▄▄▄▄▄▄▄▄


                music_layer {
//  ┌───────────────────────────────────────────────────────────┐
label= "MUSIC"                                                  ;
//  └───────────────────────────────────────────────────────────┘
/*            ┌─────────┬─────────┬─────────┬─────────┬─────────┐                    ┌─────────┬─────────┬─────────┬─────────┬─────────┐
              │    D    │   C#    │    C    │    B    │   Bb    │                    │   Bb4   │   B4    │   C5    │   C#5   │   D5    │
    ┌─────────┼─────────┼─────────┼─────────┼─────────┼─────────┤                    ├─────────┼─────────┼─────────┼─────────┼─────────┼─────────┐
    │   XXX   │    A    │   G#    │    G    │   F#    │    F    │                    │   F4    │   F#4   │   G4    │   G#4   │   A4    │   XXX   │
    ├─────────┼─────────┼─────────┼─────────┼─────────┼─────────┤╭────────╮╭────────╮├─────────┼─────────┼─────────┼─────────┼─────────┼─────────┤
    │   XXX   │    E    │   Eb    │    D    │   C#    │    C    ││  MUTE  ││PLY/PSE ││   C4    │   C#4   │   D4    │   Eb4   │   E4    │   XXX   │
    └─────────┴─────────┴─────────┼─────────┼─────────┼─────────┼╰────────╯╰────────╯┼─────────┼─────────┼─────────┼─────────┴─────────┴─────────┘
                                  │  MSEVEN │  MMINOR │  MLOWER │  MSEVEN ││  SPACE  │ SUSTAIN │ MOCTUP  │ MOCTDN  │
                                  └─────────┴─────────┴─────────┴─────────┘└─────────┴─────────┴─────────┴─────────┘ */
 bindings = <
 //|          ╷          ╷          ╷          ╷          ╷          ╷          ╷╷         ╷               ╷               ╷               ╷               ╷               ╷
              &chord_d   &chord_cs  &chord_c   &chord_b   &chord_bb                        &midi NOTE_Bb_4 &midi NOTE_B_4  &midi NOTE_C_5  &midi NOTE_Cs_5 &midi NOTE_D_5
    &trans    &chord_a   &chord_gs  &chord_g   &chord_fs  &chord_f                         &midi NOTE_F_4  &midi NOTE_Fs_4 &midi NOTE_G_4  &midi NOTE_Gs_4 &midi NOTE_A_4  &trans
    &trans    &chord_e   &chord_eb  &chord_d   &chord_cs  &chord_c   &trans     &trans     &midi NOTE_C_4  &midi NOTE_Cs_4 &midi NOTE_D_4  &midi NOTE_Eb_4 &midi NOTE_E_4  &trans
                                    &mo MSEVEN &mo MMINOR &mo MLOWER &mo MSEVEN &kp SPACE  &midi SUSTAIN   &mo MOCTUP      &mo MOCTDN
            >;
    sensor-bindings = <&inc_dec_kp C_VOL_UP C_VOL_DN>;
                };

// ▄▄▄▄▄▄▄▄▄▄▄▄▄▄▄▄▄▄▄▄▄▄▄▄▄▄▄▄▄▄▄▄▄▄▄▄▄▄▄▄▄▄▄▄▄▄▄▄▄▄▄▄▄▄▄▄▄▄▄▄▄▄▄▄▄▄▄▄▄▄▄▄▄▄▄▄▄▄▄▄▄▄▄▄▄▄▄▄▄▄▄▄▄▄▄▄▄▄▄▄▄▄▄▄▄▄▄▄▄▄▄▄▄▄▄▄▄▄▄▄▄▄▄▄▄


                mminor_layer {
//  ┌───────────────────────────────────────────────────────────┐
label= "MMINOR"                                                 ;
//  └───────────────────────────────────────────────────────────┘
 bindings = <
 //|          ╷           ╷           ╷           ╷           ╷           ╷          ╷╷         ╷         ╷         ╷         ╷         ╷         ╷
              &chord_dm   &chord_csm  &chord_cm   &chord_bm   &chord_bbm                     &trans    &trans    &trans    &trans    &trans
    &trans    &chord_am   &chord_gsm  &chord_gm   &chord_fsm  &chord_fm                      &trans    &trans    &trans    &trans    &trans    &trans
    &trans    &chord_em   &chord_ebm  &chord_dm   &chord_csm  &chord_cm   &trans     &trans  &trans    &trans    &trans    &trans    &trans    &trans
                                      &trans      &trans      &trans      &trans     &trans  &trans    &trans    &trans
            >;
    sensor-bindings = <&inc_dec_kp C_VOL_UP C_VOL_DN>;
                };

// ▄▄▄▄▄▄▄▄▄▄▄▄▄▄▄▄▄▄▄▄▄▄▄▄▄▄▄▄▄▄▄▄▄▄▄▄▄▄▄▄▄▄▄▄▄▄▄▄▄▄▄▄▄▄▄▄▄▄▄▄▄▄▄▄▄▄▄▄▄▄▄▄▄▄▄▄▄▄▄▄▄▄▄▄▄▄▄▄▄▄▄▄▄▄▄▄▄▄▄▄▄▄▄▄▄▄▄▄▄▄▄▄▄▄▄▄▄▄▄▄▄▄▄▄▄


                mseven_layer {
//  ┌───────────────────────────────────────────────────────────┐
label= "MSEVEN"                                                 ;
//  └───────────────────────────────────────────────────────────┘
 bindings = <
 //|          ╷           ╷           ╷           ╷           ╷           ╷          ╷╷         ╷         ╷         ╷         ╷         ╷         ╷
              &chord_d7   &chord_cs7  &chord_c7   &chord_b7   &chord_bb7                     &trans    &trans    &trans    &trans    &trans
    &trans    &chord_a7   &chord_gs7  &chord_g7   &chord_fs7  &chord_f7                      &trans    &trans    &trans    &trans    &trans    &trans
    &trans    &chord_e7   &chord_eb7  &chord_d7   &chord_cs7  &chord_c7   &trans     &trans  &trans    &trans    &trans    &trans    &trans    &trans
                                      &trans      &trans      &trans      &trans     &trans  &trans    &trans    &trans
            >;
    sensor-bindings = <&inc_dec_kp C_VOL_UP C_VOL_DN>;
                };

// ▄▄▄▄▄▄▄▄▄▄▄▄▄▄▄▄▄▄▄▄▄▄▄▄▄▄▄▄▄▄▄▄▄▄▄▄▄▄▄▄▄▄▄▄▄▄▄▄▄▄▄▄▄▄▄▄▄▄▄▄▄▄▄▄▄▄▄▄▄▄▄▄▄▄▄▄▄▄▄▄▄▄▄▄▄▄▄▄▄▄▄▄▄▄▄▄▄▄▄▄▄▄▄▄▄▄▄▄▄▄▄▄▄▄▄▄▄▄▄▄▄▄▄▄▄


                moctup_layer {
//  ┌───────────────────────────────────────────────────────────┐
label= "MOCTUP"                                                 ;
//  └───────────────────────────────────────────────────────────┘
 bindings = <
 //|          ╷         ╷         ╷         ╷         ╷         ╷          ╷╷         ╷               ╷               ╷               ╷               ╷               ╷
              &trans    &trans    &trans    &trans    &trans                            &midi NOTE_Bb_5 &midi NOTE_B_5  &midi NOTE_C_6  &midi NOTE_Cs_6 &midi NOTE_D_6
    &trans    &trans    &trans    &trans    &trans    &trans                            &midi NOTE_F_5  &midi NOTE_Fs_5 &midi NOTE_G_5  &midi NOTE_Gs_5 &midi NOTE_A_5  &trans
    &trans    &trans    &trans    &trans    &trans    &trans    &trans     &trans       &midi NOTE_C_5  &midi NOTE_Cs_5 &midi NOTE_D_5  &midi NOTE_Eb_5 &midi NOTE_E_5  &trans
                                  &trans    &trans    &trans    &trans     &trans       &trans          &trans          &trans
            >;
    sensor-bindings = <&inc_dec_kp C_VOL_UP C_VOL_DN>;
                };

// ▄▄▄▄▄▄▄▄▄▄▄▄▄▄▄▄▄▄▄▄▄▄▄▄▄▄▄▄▄▄▄▄▄▄▄▄▄▄▄▄▄▄▄▄▄▄▄▄▄▄▄▄▄▄▄▄▄▄▄▄▄▄▄▄▄▄▄▄▄▄▄▄▄▄▄▄▄▄▄▄▄▄▄▄▄▄▄▄▄▄▄▄▄▄▄▄▄▄▄▄▄▄▄▄▄▄▄▄▄▄▄▄▄▄▄▄▄▄▄▄▄▄▄▄▄


                moctdn_layer {
//  ┌───────────────────────────────────────────────────────────┐
label= "MOCTDN"                                                 ;
//  └───────────────────────────────────────────────────────────┘
 bindings = <
 //|          ╷         ╷         ╷         ╷         ╷         ╷          ╷╷         ╷               ╷               ╷               ╷               ╷               ╷
              &trans    &trans    &trans    &trans    &trans                            &midi NOTE_Bb_3 &midi NOTE_B_3  &midi NOTE_C_4  &midi NOTE_Cs_4 &midi NOTE_D_4
    &trans    &trans    &trans    &trans    &trans    &trans                            &midi NOTE_F_3  &midi NOTE_Fs_3 &midi NOTE_G_3  &midi NOTE_Gs_3 &midi NOTE_A_3  &trans
    &trans    &trans    &trans    &trans    &trans    &trans    &trans     &trans       &midi NOTE_C_3  &midi NOTE_Cs_3 &midi NOTE_D_3  &midi NOTE_Eb_3 &midi NOTE_E_3  &trans
                                  &trans    &trans    &trans    &trans     &trans       &trans          &trans          &trans
            >;
    sensor-bindings = <&inc_dec_kp C_VOL_UP C_VOL_DN>;
                };

// ▄▄▄▄▄▄▄▄▄▄▄▄▄▄▄▄▄▄▄▄▄▄▄▄▄▄▄▄▄▄▄▄▄▄▄▄▄▄▄▄▄▄▄▄▄▄▄▄▄▄▄▄▄▄▄▄▄▄▄▄▄▄▄▄▄▄▄▄▄▄▄▄▄▄▄▄▄▄▄▄▄▄▄▄▄▄▄▄▄▄▄▄▄▄▄▄▄▄▄▄▄▄▄▄▄▄▄▄▄▄▄▄▄▄▄▄▄▄▄▄▄▄▄▄▄


                mlower_layer {
//  ┌───────────────────────────────────────────────────────────┐
label= "MLOWER"                                                 ;
//  └───────────────────────────────────────────────────────────┘
/*            ┌─────────┬─────────┬─────────┬─────────┬─────────┐                    ┌─────────┬─────────┬─────────┬─────────┬─────────┐
              │         │         │         │         │  PANIC  │                    │         │         │         │ RECORD  │  LOOP   │
    ┌─────────┼─────────┼─────────┼─────────┼─────────┼─────────┤                    ├─────────┼─────────┼─────────┼─────────┼─────────┼─────────┐
    │         │         │         │         │         │         │                    │         │         │         │         │         │         │
    ├─────────┼─────────┼─────────┼─────────┼─────────┼─────────┤╭────────╮╭────────╮├─────────┼─────────┼─────────┼─────────┼─────────┼─────────┤
    │         │         │         │         │         │         ││        ││        ││  METRO  │         │         │         │  UNDO   │         │
    └─────────┴─────────┴─────────┼─────────┼─────────┼─────────┼╰────────╯╰────────╯┼─────────┼─────────┼─────────┼─────────┴─────────┴─────────┘
                                  │         │         │         │         ││         │ ADJUST  │         │         │
                                  └─────────┴─────────┴─────────┴─────────┘└─────────┴─────────┴─────────┴─────────┘ */
 bindings = <
 //|          ╷         ╷         ╷         ╷          ╷                  ╷          ╷╷         ╷         ╷         ╷         ╷         ╷         ╷         ╷
              &trans    &trans    &trans    &trans     &midi ALL_NOTES_OFF                      &trans    &trans    &trans    &kp R     &kp L
    &trans    &trans    &trans    &trans    &trans     &trans                                   &trans    &trans    &trans    &trans    &trans    &trans
    &trans    &trans    &trans    &trans    &trans     &trans             &trans     &trans     &kp B     &trans    &trans    &trans    &kp LC(Z) &trans
                                            &trans     &trans             &trans     &trans     &trans    &mo ADJUST &trans   &trans
            >;
    sensor-bindings = <&inc_dec_kp C_VOL_UP C_VOL_DN>;
                };

// ▄▄▄▄▄▄▄▄▄▄▄▄▄▄▄▄▄▄▄▄▄▄▄▄▄▄▄▄▄▄▄▄▄▄▄▄▄▄▄▄▄▄▄▄▄▄▄▄▄▄▄▄▄▄▄▄▄▄▄▄▄▄▄▄▄▄▄▄▄▄▄▄▄▄▄▄▄▄▄▄▄▄▄▄▄▄▄▄▄▄▄▄▄▄▄▄▄▄▄▄▄▄▄▄▄▄▄▄▄▄▄▄▄▄▄▄▄▄▄▄▄▄▄▄▄


                adjust_layer {
//  ┌───────────────────────────────────────────────────────────┐
label= "ADJUST"                                                 ;
//  └───────────────────────────────────────────────────────────┘
/*           ┌─────────┬─────────┬─────────┬─────────┬─────────┐                    ┌─────────┬─────────┬─────────┬─────────┬─────────┐
             │         │         │         │         │  gaming │                    │         │         │         │         │         │
   ┌─────────┼─────────┼─────────┼─────────┼─────────┼─────────┤                    ├─────────┼─────────┼─────────┼─────────┼─────────┼─────────┐
   │         │         │         │         │         │  music  │                    │         │         │         │         │         │         │
   ├─────────┼─────────┼─────────┼─────────┼─────────┼─────────┤╭────────╮╭────────╮├─────────┼─────────┼─────────┼─────────┼─────────┼─────────┤
   │         │         │         │         │         │         ││        ││        ││         │         │         │         │         │         │
   └─────────┴─────────┴─────────┼─────────┼─────────┼─────────┼╰────────╯╰────────╯┼─────────┼─────────┼─────────┼─────────┴─────────┴─────────┘
                                 │         │         │         │         ││         │         │         │         │
                                 └─────────┴─────────┴─────────┴─────────┘└─────────┴─────────┴─────────┴─────────┘ */ 
 bindings = <
 //╷         ╷         ╷         ╷         ╷         ╷         ╷         ╷╷         ╷         ╷         ╷         ╷         ╷         ╷         ╷
             &bt BT_CLR &trans    &trans    &trans    &tog GAMING                    &trans    &trans    &trans    &trans    &bt BT_CLR
    &trans   &bt BT_NXT &trans    &trans    &trans    &tog MUSIC                     &trans    &trans    &trans    &bt BT_NXT &trans   &trans
    &trans   &bt BT_PRV &trans    &trans    &kp KP_N6 &trans    &trans     &trans    &bt BT_PRV &trans   &trans    &trans    &trans    &trans
                                  &trans    &trans    &trans    &trans     &trans    &trans    &trans    &trans
                        >;
            sensor-bindings = <&inc_dec_kp C_VOL_UP C_VOL_DN>;
                };
        };
};
